# PIC32MK1024MCF100 register map
Vendor: Microchip
Registers are 32-bit, read-write, reset 0x0 unless marked. A register's access mark holds for its fields unless they carry their own. Addresses are absolute, and some are shared; only a register's first bit layout is shown; [hi:lo] are bit positions; {n}, {i} and the like mark numbered series.

## PORTF
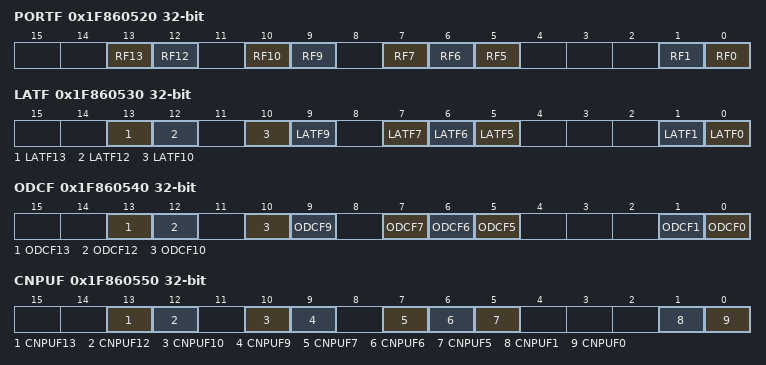
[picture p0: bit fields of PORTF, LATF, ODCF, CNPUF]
0x1F860520 PORTF reset not defined — (power-on value ------------------xx-xx-xxx---xx)
  [13] RF13, [12] RF12, [10] RF10, [9] RF9, [7] RF7, [6] RF6, [5] RF5, [1] RF1, [0] RF0
0x1F860530 LATF reset not defined — (power-on value ------------------xx-xx-xxx---xx)
  [13] LATF13, [12] LATF12, [10] LATF10, [9] LATF9, [7] LATF7, [6] LATF6, [5] LATF5, [1] LATF1, [0] LATF0
0x1F860540 ODCF
  [13] ODCF13, [12] ODCF12, [10] ODCF10, [9] ODCF9, [7] ODCF7, [6] ODCF6, [5] ODCF5, [1] ODCF1, [0] ODCF0
0x1F860550 CNPUF
  [13] CNPUF13, [12] CNPUF12, [10] CNPUF10, [9] CNPUF9, [7] CNPUF7, [6] CNPUF6, [5] CNPUF5, [1] CNPUF1, [0] CNPUF0
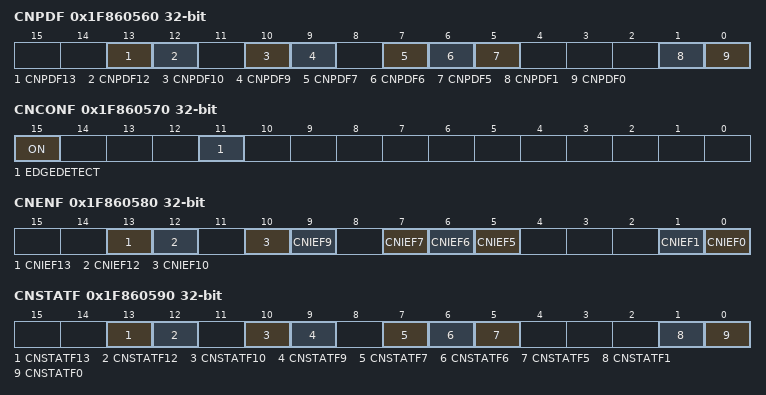
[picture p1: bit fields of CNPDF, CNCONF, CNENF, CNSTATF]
0x1F860560 CNPDF
  [13] CNPDF13, [12] CNPDF12, [10] CNPDF10, [9] CNPDF9, [7] CNPDF7, [6] CNPDF6, [5] CNPDF5, [1] CNPDF1, [0] CNPDF0
0x1F860570 CNCONF
  [15] ON, [11] EDGEDETECT
0x1F860580 CNENF
  [13] CNIEF13, [12] CNIEF12, [10] CNIEF10, [9] CNIEF9, [7] CNIEF7, [6] CNIEF6, [5] CNIEF5, [1] CNIEF1, [0] CNIEF0
0x1F860590 CNSTATF
  [13] CNSTATF13, [12] CNSTATF12, [10] CNSTATF10, [9] CNSTATF9, [7] CNSTATF7, [6] CNSTATF6, [5] CNSTATF5, [1] CNSTATF1, [0] CNSTATF0
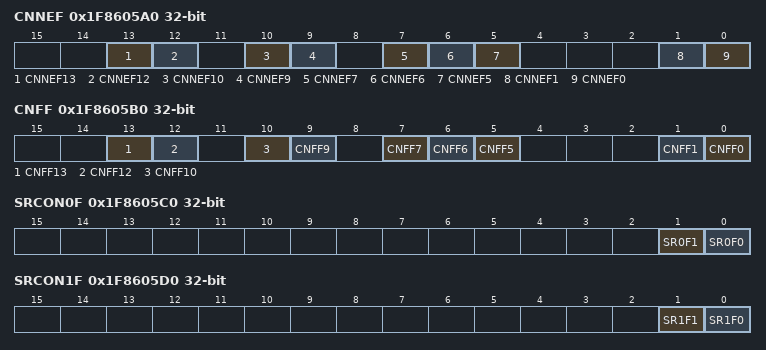
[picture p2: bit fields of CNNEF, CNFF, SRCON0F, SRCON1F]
0x1F8605A0 CNNEF
  [13] CNNEF13, [12] CNNEF12, [10] CNNEF10, [9] CNNEF9, [7] CNNEF7, [6] CNNEF6, [5] CNNEF5, [1] CNNEF1, [0] CNNEF0
0x1F8605B0 CNFF
  [13] CNFF13, [12] CNFF12, [10] CNFF10, [9] CNFF9, [7] CNFF7, [6] CNFF6, [5] CNFF5, [1] CNFF1, [0] CNFF0
0x1F8605C0 SRCON0F
  [1] SR0F1, [0] SR0F0
0x1F8605D0 SRCON1F
  [1] SR1F1, [0] SR1F0

## PORTG
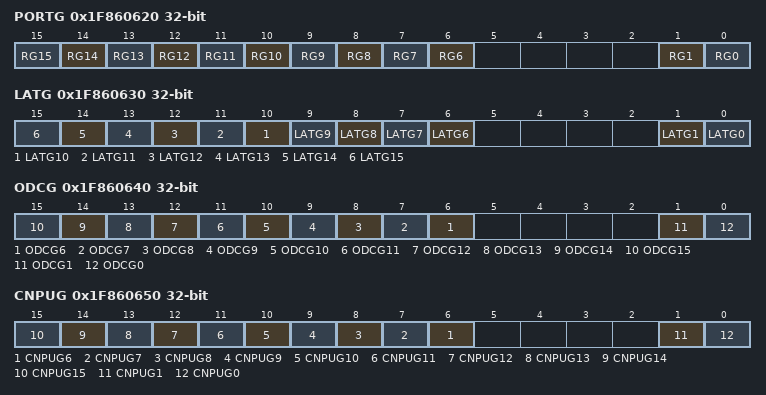
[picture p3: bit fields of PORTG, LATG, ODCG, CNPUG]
0x1F860620 PORTG reset not defined — (power-on value ----------------xxxxxxxxxx----xx)
  [n] RG{n} (n=6..15), [1] RG1, [0] RG0
0x1F860630 LATG reset not defined — (power-on value ----------------xxxxxxxxxx----xx)
  [n] LATG{n} (n=6..15), [1] LATG1, [0] LATG0
0x1F860640 ODCG
  [n] ODCG{n} (n=6..15), [1] ODCG1, [0] ODCG0
0x1F860650 CNPUG
  [n] CNPUG{n} (n=6..15), [1] CNPUG1, [0] CNPUG0
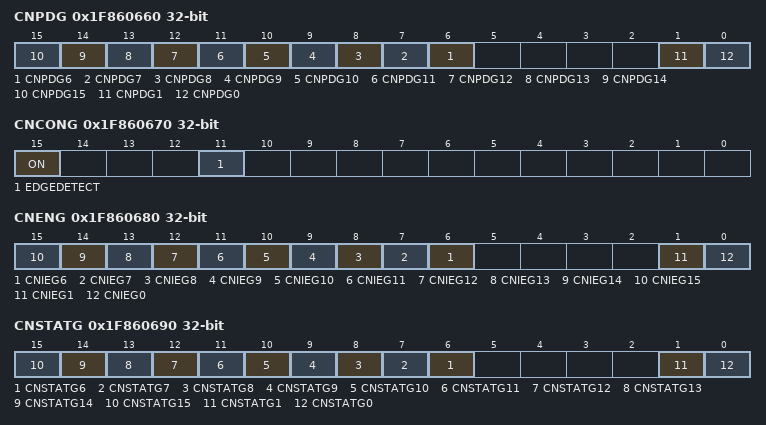
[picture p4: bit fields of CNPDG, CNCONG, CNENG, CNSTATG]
0x1F860660 CNPDG
  [n] CNPDG{n} (n=6..15), [1] CNPDG1, [0] CNPDG0
0x1F860670 CNCONG
  [15] ON, [11] EDGEDETECT
0x1F860680 CNENG
  [n] CNIEG{n} (n=6..15), [1] CNIEG1, [0] CNIEG0
0x1F860690 CNSTATG
  [n] CNSTATG{n} (n=6..15), [1] CNSTATG1, [0] CNSTATG0
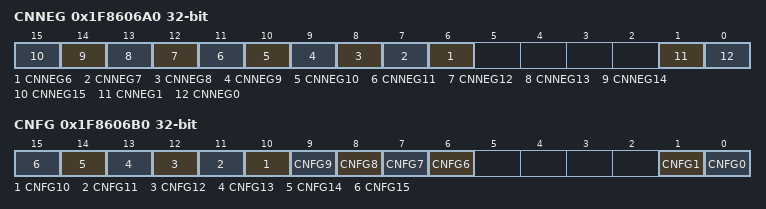
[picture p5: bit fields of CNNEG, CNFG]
0x1F8606A0 CNNEG
  [n] CNNEG{n} (n=6..15), [1] CNNEG1, [0] CNNEG0
0x1F8606B0 CNFG
  [n] CNFG{n} (n=6..15), [1] CNFG1, [0] CNFG0

## CAN1
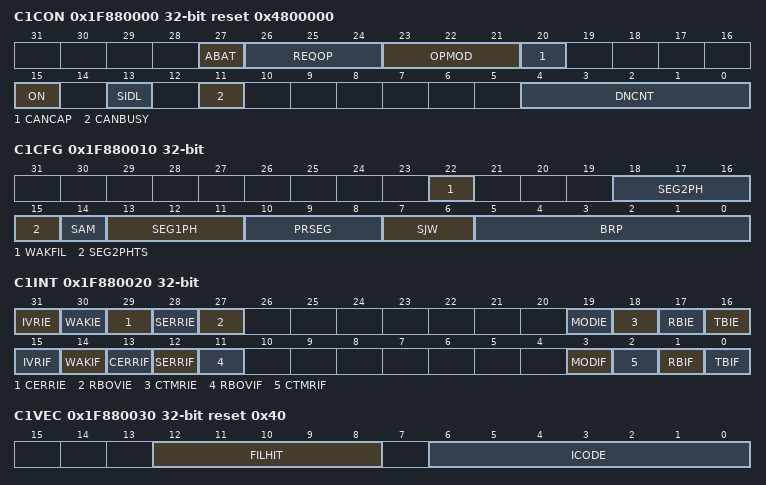
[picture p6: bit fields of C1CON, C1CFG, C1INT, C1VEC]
0x1F880000 C1CON reset 0x4800000
  [27] ABAT — (can only be set)
  [26:24] REQOP
  [23:21] OPMOD ro
  [20] CANCAP
  [15] ON
  [13] SIDL
  [11] CANBUSY ro
  [4:0] DNCNT
0x1F880010 C1CFG
  [22] WAKFIL, [18:16] SEG2PH, [15] SEG2PHTS, [14] SAM, [13:11] SEG1PH, [10:8] PRSEG, [7:6] SJW, [5:0] BRP
0x1F880020 C1INT
  [31] IVRIE, [30] WAKIE, [29] CERRIE, [28] SERRIE, [27] RBOVIE, [19] MODIE, [18] CTMRIE, [17] RBIE, [16] TBIE, [15] IVRIF, [14] WAKIF, [13] CERRIF, [12] SERRIF, [11] RBOVIF, [3] MODIF, [2] CTMRIF, [1] RBIF, [0] TBIF
0x1F880030 C1VEC ro reset 0x40
  [12:8] FILHIT, [6:0] ICODE
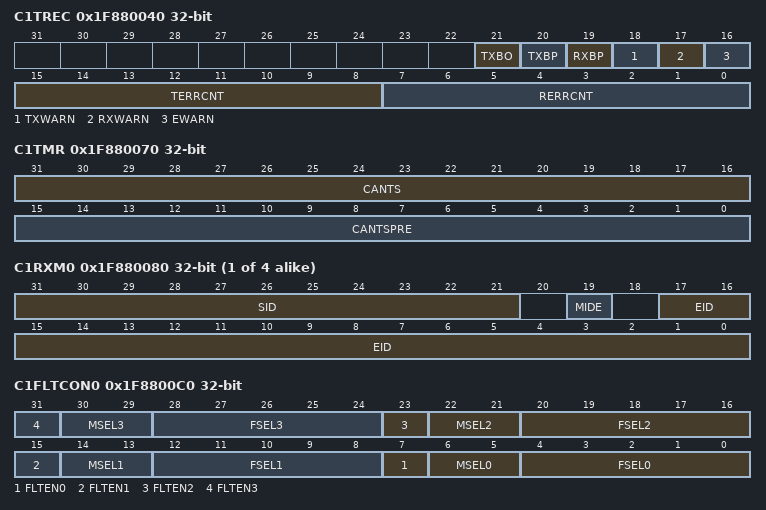
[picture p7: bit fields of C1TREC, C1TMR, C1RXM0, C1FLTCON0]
0x1F880040 C1TREC ro
  [21] TXBO, [20] TXBP, [19] RXBP, [18] TXWARN, [17] RXWARN, [16] EWARN, [15:8] TERRCNT, [7:0] RERRCNT
0x1F880050 C1FSTAT ro
  [15:0] FIFOIP
0x1F880060 C1RXOVF ro
  [15:0] RXOVF
0x1F880070 C1TMR
  [31:16] CANTS, [15:0] CANTSPRE
{0x1F880080+0x10*i} C1RXM{i} (i=0..3)
  [31:21] SID, [19] MIDE, [17:0] EID
0x1F8800C0 C1FLTCON0
  [8n+7] FLTEN{n} (n=0..3), [8n+6:8n+5] MSEL{n} (n=0..3), [8n+4:8n] FSEL{n} (n=0..3)
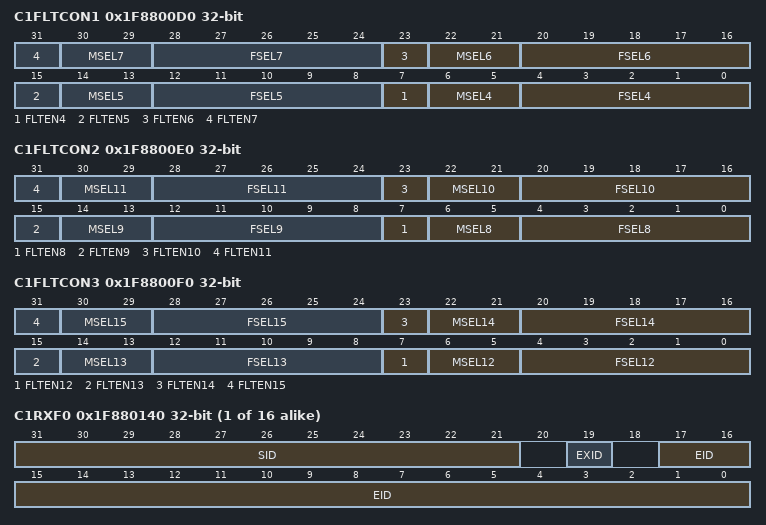
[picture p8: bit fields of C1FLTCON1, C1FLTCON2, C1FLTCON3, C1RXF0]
0x1F8800D0 C1FLTCON1
  [8n-25] FLTEN{n} (n=4..7), [8n-26:8n-27] MSEL{n} (n=4..7), [8n-28:8n-32] FSEL{n} (n=4..7)
0x1F8800E0 C1FLTCON2
  [8n-57] FLTEN{n} (n=8..11), [8n-58:8n-59] MSEL{n} (n=8..11), [8n-60:8n-64] FSEL{n} (n=8..11)
0x1F8800F0 C1FLTCON3
  [8n-89] FLTEN{n} (n=12..15), [8n-90:8n-91] MSEL{n} (n=12..15), [8n-92:8n-96] FSEL{n} (n=12..15)
{0x1F880140+0x10*i} C1RXF{i} reset not defined (i=0..15) — (power-on value xxxxxxxxxxx0x0xxxxxxxxxxxxxxxxxx)
  [31:21] SID, [19] EXID, [17:0] EID
0x1F880340 C1FIFOBA
  [31:2] FIFOBA
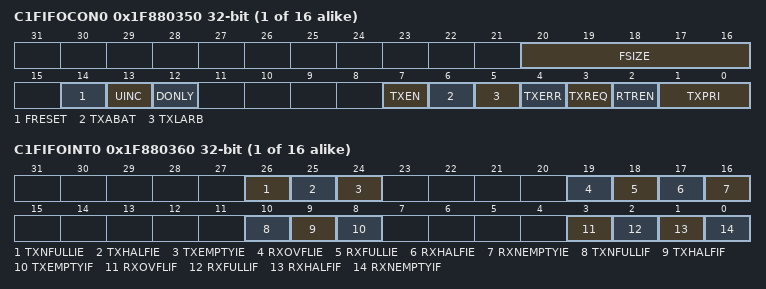
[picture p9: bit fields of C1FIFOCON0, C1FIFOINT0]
{0x1F880350+0x40*i} C1FIFOCON{i} (i=0..15)
  [20:16] FSIZE, [14] FRESET, [13] UINC, [12] DONLY, [7] TXEN, [6] TXABAT, [5] TXLARB, [4] TXERR, [3] TXREQ, [2] RTREN, [1:0] TXPRI
{0x1F880360+0x40*i} C1FIFOINT{i} (i=0..15)
  [26] TXNFULLIE, [25] TXHALFIE, [24] TXEMPTYIE, [19] RXOVFLIE, [18] RXFULLIE, [17] RXHALFIE, [16] RXNEMPTYIE, [10] TXNFULLIF ro, [9] TXHALFIF ro, [8] TXEMPTYIF ro, [3] RXOVFLIF, [2] RXFULLIF ro, [1] RXHALFIF ro, [0] RXNEMPTYIF ro
{0x1F880370+0x40*i} C1FIFOUA{i} ro reset not defined (i=0..15) — (power-on value xxxxxxxxxxxxxxxxxxxxxxxxxxxxxx00)
  [31:2] FIFOUA
{0x1F880380+0x40*i} C1FIFOCI{i} ro (i=0..15)
  [4:0] CFIFOCI
